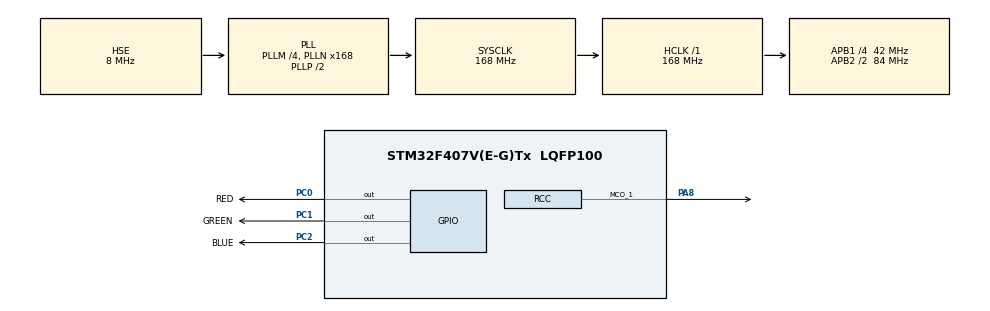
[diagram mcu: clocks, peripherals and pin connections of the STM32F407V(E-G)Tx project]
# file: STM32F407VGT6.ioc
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Mcu.Family=STM32F4
Mcu.Name=STM32F407V(E-G)Tx
Mcu.Package=LQFP100
NVIC.PriorityGroup=NVIC_PRIORITYGROUP_4
PA10.Signal=USART1_RX
PA11.Signal=USB_OTG_FS_DM
PA12.Signal=USB_OTG_FS_DP
PA13.Mode=Serial_Wire
PA13.Signal=SYS_JTMS-SWDIO
PA14.Mode=Serial_Wire
PA14.Signal=SYS_JTCK-SWCLK
PA4.Signal=DCMI_HSYNC
PA6.Signal=DCMI_PIXCLK
PA8.Mode=Clock-out-1
PA8.Signal=RCC_MCO_1
PA9.Signal=USART1_TX
PB10.Signal=SPI2_SCK
PB12.Signal=SPI2_NSS
PB14.Signal=SPI2_MISO
PB15.Signal=SPI2_MOSI
PB6.Signal=DCMI_D5
PB7.Signal=DCMI_VSYNC
PB8.Signal=I2C1_SCL
PB9.Signal=I2C1_SDA
PC0.GPIO_Label=RED
PC0.GPIO_PuPd=GPIO_PULLUP
PC0.PinState=GPIO_PIN_SET
PC0.Signal=GPIO_Output
PC1.GPIO_Label=GREEN
PC1.GPIO_PuPd=GPIO_PULLUP
PC1.PinState=GPIO_PIN_SET
PC1.Signal=GPIO_Output
PC10.Signal=SDIO_D2
PC11.Signal=SDIO_D3
PC12.Signal=SDIO_CK
PC2.GPIO_Label=BLUE
PC2.GPIO_PuPd=GPIO_PULLUP
PC2.PinState=GPIO_PIN_SET
PC2.Signal=GPIO_Output
PC6.Signal=DCMI_D0
PC7.Signal=DCMI_D1
PC8.Signal=SDIO_D0
PC9.Signal=SDIO_D1
PD2.Signal=SDIO_CMD
PE0.Signal=DCMI_D2
PE1.Signal=DCMI_D3
PE4.Signal=DCMI_D4
PE5.Signal=DCMI_D6
PE6.Signal=DCMI_D7
PH0-OSC_IN.Mode=HSE-External-Oscillator
PH0-OSC_IN.Signal=RCC_OSC_IN
PH1-OSC_OUT.Mode=HSE-External-Oscillator
PH1-OSC_OUT.Signal=RCC_OSC_OUT
ProjectManager.HeapSize=0x800
ProjectManager.StackSize=0x800
ProjectManager.TargetToolchain=MDK-ARM V5.32
RCC.48MHZClocksFreq_Value=84000000
RCC.AHBFreq_Value=168000000
RCC.APB1CLKDivider=RCC_HCLK_DIV4
RCC.APB1Freq_Value=42000000
RCC.APB1TimFreq_Value=84000000
RCC.APB2CLKDivider=RCC_HCLK_DIV2
RCC.APB2Freq_Value=84000000
RCC.APB2TimFreq_Value=168000000
RCC.CortexFreq_Value=168000000
RCC.HCLKFreq_Value=168000000
RCC.HSE_VALUE=8000000
RCC.HSI_VALUE=16000000
RCC.LSE_VALUE=32768
RCC.PLLM=4
RCC.PLLN=168
RCC.PLLSourceVirtual=RCC_PLLSOURCE_HSE
RCC.SYSCLKFreq_VALUE=168000000
RCC.SYSCLKSource=RCC_SYSCLKSOURCE_PLLCLK
RCC.VCOOutputFreq_Value=336000000
board=custom

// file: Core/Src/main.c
/* USER CODE BEGIN Header */
/**
  ******************************************************************************
  * @file           : main.c
  * @brief          : Main program body
  ******************************************************************************
  * @attention
  *
  * <h2><center>&copy; Copyright (c) 2022 STMicroelectronics.
  * All rights reserved.</center></h2>
  *
  * This software component is licensed by ST under BSD 3-Clause license,
  * the "License"; You may not use this file except in compliance with the
  * License. You may obtain a copy of the License at:
  *                        opensource.org/licenses/BSD-3-Clause
  *
  ******************************************************************************
  */
/* USER CODE END Header */
#include "main.h"
#include "gpio.h"

void SystemClock_Config(void);

int main(void)
{

  /* MCU Configuration--------------------------------------------------------*/

  /* Reset of all peripherals, Initializes the Flash interface and the Systick. */
  HAL_Init();

  /* Configure the system clock */
  SystemClock_Config();

  /* Initialize all configured peripherals */
  MX_GPIO_Init();

  /* Infinite loop */
  /* USER CODE BEGIN WHILE */
  while (1)
  {
		HAL_GPIO_TogglePin(RED_GPIO_Port,RED_Pin);
		HAL_GPIO_TogglePin(GREEN_GPIO_Port,GREEN_Pin);
		HAL_GPIO_TogglePin(BLUE_GPIO_Port,BLUE_Pin);
		HAL_Delay(200);
    /* USER CODE END WHILE */

  }
}

void SystemClock_Config(void)
{
  RCC_OscInitTypeDef RCC_OscInitStruct = {0};
  RCC_ClkInitTypeDef RCC_ClkInitStruct = {0};

  /** Configure the main internal regulator output voltage
  */
  __HAL_RCC_PWR_CLK_ENABLE();
  __HAL_PWR_VOLTAGESCALING_CONFIG(PWR_REGULATOR_VOLTAGE_SCALE1);

  /** Initializes the RCC Oscillators according to the specified parameters
  * in the RCC_OscInitTypeDef structure.
  */
  RCC_OscInitStruct.OscillatorType = RCC_OSCILLATORTYPE_HSI|RCC_OSCILLATORTYPE_HSE;
  RCC_OscInitStruct.HSEState = RCC_HSE_ON;
  RCC_OscInitStruct.HSIState = RCC_HSI_ON;
  RCC_OscInitStruct.HSICalibrationValue = RCC_HSICALIBRATION_DEFAULT;
  RCC_OscInitStruct.PLL.PLLState = RCC_PLL_ON;
  RCC_OscInitStruct.PLL.PLLSource = RCC_PLLSOURCE_HSE;
  RCC_OscInitStruct.PLL.PLLM = 4;
  RCC_OscInitStruct.PLL.PLLN = 168;
  RCC_OscInitStruct.PLL.PLLP = RCC_PLLP_DIV2;
  RCC_OscInitStruct.PLL.PLLQ = 4;
  if (HAL_RCC_OscConfig(&RCC_OscInitStruct) != HAL_OK)
  {
    Error_Handler();
  }

  /** Initializes the CPU, AHB and APB buses clocks
  */
  RCC_ClkInitStruct.ClockType = RCC_CLOCKTYPE_HCLK|RCC_CLOCKTYPE_SYSCLK
                              |RCC_CLOCKTYPE_PCLK1|RCC_CLOCKTYPE_PCLK2;
  RCC_ClkInitStruct.SYSCLKSource = RCC_SYSCLKSOURCE_PLLCLK;
  RCC_ClkInitStruct.AHBCLKDivider = RCC_SYSCLK_DIV1;
  RCC_ClkInitStruct.APB1CLKDivider = RCC_HCLK_DIV4;
  RCC_ClkInitStruct.APB2CLKDivider = RCC_HCLK_DIV2;

  if (HAL_RCC_ClockConfig(&RCC_ClkInitStruct, FLASH_LATENCY_5) != HAL_OK)
  {
    Error_Handler();
  }
  HAL_RCC_MCOConfig(RCC_MCO1, RCC_MCO1SOURCE_HSI, RCC_MCODIV_1);
}

void Error_Handler(void)
{
  __disable_irq();
  while (1)
  {
  }
}
